# MSPM0L222X register map
Vendor: Texas Instruments; File version: This preliminary header file does not have a version number - build date: 2024-04-29 20:57:13
CPU: CM0 r0p1, little endian, MPU, no FPU, 3 interrupt priority bits
Registers are 32-bit, read-write, reset 0x0 unless marked. A register's access mark holds for its fields unless they carry their own. Offsets are from the block's base; [hi:lo] are bit positions; lines under a group give offsets from that group; {n}, {i} and the like mark numbered series.

## ADC0_SVT — PERIPHERALREGIONSVT
Base 0x4055A000
0x556160 ADC0_SVT_FIFODATA ro — FIFO Data Register
{0x556280+4i} ADC0_SVT_MEMRES[{i}] (i=0..11) ro — Memory Result Register
  [15:0] DATA — MEMRES result register. If DF = 0, unsigned binary: The conversion results are right aligned. In 10 and 8 bit modes, the unused MSB bits are forced to 0. If DF = 1, 2s-complement format: The conversion results are left aligned. In 10 and 8 bit modes, the unused LSB bits are forced to 0. The data is stored in the right-justified format and is converted to the left-justified 2s-complement format during read back.

## VREF — PERIPHERALREGION
Base 0x40030000
{0x800+0x18*i} VREF_GPRCM[{i}] (i=0..0) group
  0x00 VREF_PWREN — Power enable
    [0] ENABLE — Enable the power
      0=DISABLE (Disable Power); 1=ENABLE (Enable Power)
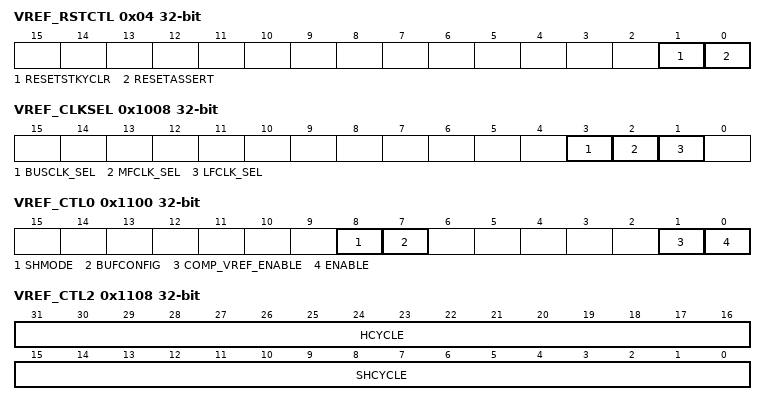
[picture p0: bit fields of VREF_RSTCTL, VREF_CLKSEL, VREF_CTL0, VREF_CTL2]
  0x04 VREF_RSTCTL wo — Reset Control
    [1] RESETSTKYCLR — Clear the RESETSTKY bit in the STAT register
      0=NOP (Writing 0 has no effect); 1=CLR (Clear reset sticky bit)
    [0] RESETASSERT — Assert reset to the peripheral
      0=NOP (Writing 0 has no effect); 1=ASSERT (Assert reset)
  0x14 VREF_STAT ro — Status Register
    [16] RESETSTKY — This bit indicates, if the peripheral was reset, since this bit was cleared by RESETSTKYCLR in the RSTCTL register
      0=NORES (The peripheral has not been reset since this bit was last cleared by RESETSTKYCLR in the RSTCTL register); 1=RESET (The peripheral was reset since the last bit clear)
0x1000 VREF_CLKDIV — Clock Divider
  [2:0] RATIO — Selects divide ratio of module clock to be used in sample and hold logic
0x1008 VREF_CLKSEL — Clock Selection
  [3] BUSCLK_SEL — Selects BUSCLK as clock source if enabled
  [2] MFCLK_SEL — Selects MFCLK as clock source if enabled
  [1] LFCLK_SEL — Selects LFCLK as clock source if enabled
0x1100 VREF_CTL0 — Control 0
  [8] SHMODE — This bit enable sample and hold mode
    0=DISABLE (Sample and hold mode is disable); 1=Enable (Sample and hold mode is enable)
  [7] BUFCONFIG — These bits configure output buffer.
    0=OUTPUT2P5V (Configure Output Buffer to 2.5v); 1=OUTPUT1P4V (Configure Output Buffer to 1.4v)
  [1] COMP_VREF_ENABLE — Comparator Vref Enable
    0=DISABLE (COMP VREF is disabled); 1=ENABLE (COMP VREF is enabled)
  [0] ENABLE — This bit enables the VREF module.
    0=DISABLE (VREF is disabled); 1=ENABLE (VREF is enabled)
0x1104 VREF_CTL1 — Control 1
  [0] READY ro — These bits defines status of VREF
    0=NOTRDY (VREF output is not ready); 1=RDY (VREF output is ready)
0x1108 VREF_CTL2 — Control 2
  [31:16] HCYCLE — Hold cycle count Total cycles of module clock for hold phase when VREF is working in sample and hold mode in STANDBY to save power. Please refer VREF section of datasheet for recommended values of sample and hold times.
  [15:0] SHCYCLE — Sample and Hold cycle count Total cycles of module clock for sample and hold phase when VREF is working in sample and hold mode in STANDBY to save power. This field should be greater than HCYCLE field. The difference between this field and HCYCLE gives the number of cycles of sample phase. Please refer VREF section of datasheet for recommended values of sample and hold times.

## KEYSTORECTL — PERIPHERALREGION
Base 0x400AC000
0x1100 KEYSTORECTL_CFG reset 0x1 — Keystore configuration
  [3:0] NK256 — Number of 256 bit keys to be held in the key-store. Can not exceed the total number of slots present in the hardware / 2. For eg: if SYS_N_SLOTS = 4, then atmost 2 256-bit keys can be held in the key-store. Incorrect setting of this field will be reported via STATUS register
    0=ZERO (No 256-bit keys); 1=ONE (One 256-bit key); 2=TWO (Two 256-bit keys); 3=THREE (Three 256-bit keys); 4=FOUR (Four 256-bit keys)
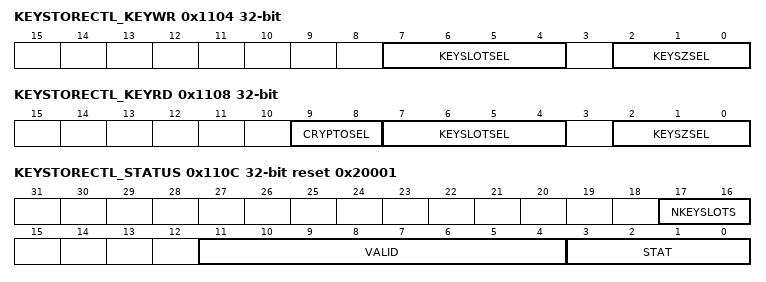
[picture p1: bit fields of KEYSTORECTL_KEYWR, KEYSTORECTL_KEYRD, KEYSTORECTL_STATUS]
0x1104 KEYSTORECTL_KEYWR — Key write configuration
  [7:4] KEYSLOTSEL — Select the key slot to write the key into. NOTE: SW needs to ensure that it is writing to the correct slots. The slot numbering is from 0 through SYS_N_SLOTS-1. Each slot is a 128-bit slot. Therefore, when writing a 256-bit key, two slots will need to budgeted.
    {v}=SLOT{v} (v=0..7)
  [2:0] KEYSZSEL — Key size selection. Selection of 128 or 256 bit keys
    0=K256 (256 bit key); 1=K128 (128 bit key)
0x1108 KEYSTORECTL_KEYRD — Key read configuration
  [9:8] CRYPTOSEL — Crypto engine selector
    0=AES (Transfer key to AES)
  [7:4] KEYSLOTSEL — Select the key slot to read the key from. NOTE: SW needs to ensure that it is reading from the correct slots. The slot numbering is from 0 through SYS_N_SLOTS-1. Each slot is a 128-bit slot. Therefore, when reading a 256-bit key, two adjacent slots will be read.
  [2:0] KEYSZSEL — Key size selection. Selection of 128 or 256 bit keys
    0=K256 (256 bit key); 1=K128 (128 bit key)
0x110C KEYSTORECTL_STATUS ro reset 0x20001 — Status
  [17:16] NKEYSLOTS — Size of keystorage: Number of 128-bit key slots
    0=TWO (Two slots); 1=THREE (Three slots); 2=FOUR (Four slots)
  [11:4] VALID — Bitvector of valid bits to indicate which slots have been configured
  [3:0] STAT — Status information
    0=VALID (Valid configuration); 1=NO_CFG (Key-store has not been configured. NK256 has not been set.); 2=INVALID_NK256 (Invalid value for NK256 field in CFG.); 3=BUSY_RECEIVE (Busy receiving a key deposit); 4=BUSY_TRANSMIT (Busy transmitting a key to a crypto engine); 5=INVALID_KEYSLOTSELW (Invalid keyslot selection for writing); 6=INVALID_KEYSLOTSELR (Invalid keyslot selection for reading)
0x1110 KEYSTORECTL_KEYIN wo — Input key

## IOMUX — PERIPHERALREGION
Base 0x40428000
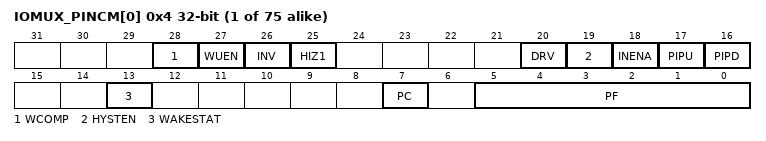
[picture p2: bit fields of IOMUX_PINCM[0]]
{0x4+4i} IOMUX_PINCM[{i}] (i=0..74) — Pin Control Management Register in SECCFG region
  [28] WCOMP — Wakeup Compare Value bit
    0=MATCH0 (Wakeup on a match of 0); 1=MATCH1 (Wakeup on a match of 1)
  [27] WUEN — Wakeup Enable bit
    0=DISABLE (wakeup is disabled.); 1=ENABLE (wakeup is enabled)
  [26] INV — Data inversion selection
    0=DISABLE (Data inversion is disabled.); 1=ENABLE (Data inversion is enabled)
  [25] HIZ1 — High output value will tri-state the output when this bit is enabled
    0=DISABLE (open-drain is disabled.); 1=ENABLE (open-drain is enabled.)
  [20] DRV — Drive strength control selection, for HS IOCELL only
    0=DRVVAL0 (Drive setting of 0 selected); 1=DRVVAL1 (Drive setting of 1 selected)
  [19] HYSTEN — Hystersis Enable Control Selection
    0=DISABLE (hysteresis is disabled.); 1=ENABLE (hysteresis is enabled)
  [18] INENA — Input Enable Control Selection
    0=DISABLE (Input enable is disabled.); 1=ENABLE (Input enable is enabled.)
  [17] PIPU — Pull Up control selection
    0=DISABLE (Pull up is disabled.); 1=ENABLE (Pull up is enabled)
  [16] PIPD — Pull Down control selection
    0=DISABLE (Pull down is disabled.); 1=ENABLE (Pull down is enabled)
  [13] WAKESTAT ro — This has the IOPAD WAKEUP signal as status bit.
    0=DISABLE (wakeup source is NOT from this IOCELL); 1=ENABLE (wakeup source is from this IOCELL)
  [7] PC — Peripheral is Connected
    0=UNCONNECTED (The output of the peripheral (and its output enable) will not propagate to the IOCELL); 1=CONNECTED (The output latch of the dataflow will be transparent)
  [5:0] PF — P channel Function selection bits
